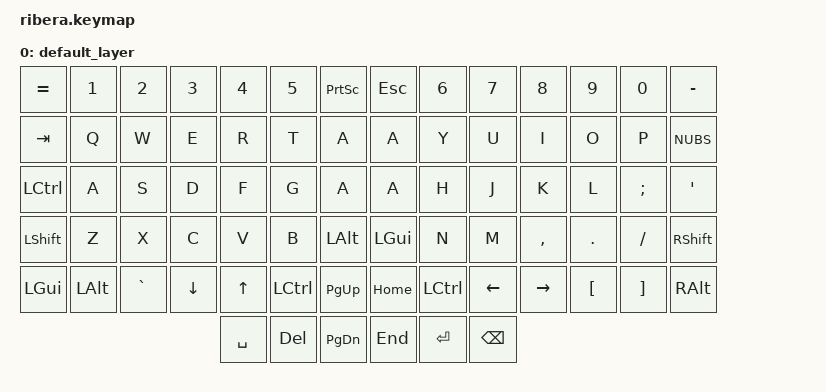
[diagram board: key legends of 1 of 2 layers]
#include <behaviors.dtsi>
#include <dt-bindings/zmk/keys.h>
#include <dt-bindings/zmk/bt.h>

/ {
        keymap {
                compatible = "zmk,keymap";

                default_layer {
// ---------------------------------------------------------------------------------
// |   `  |  1  |  2  |  3  |  4  |  5  |  prt  |       |  6  |  7  |  8  |  9  |  0  | BKSP |
// |  TAB |  Q  |  W  |  E  |  R  |  T  |  Mac  |       |  Y  |  U  |  I  |  O  |  P  |  \   |
// | CAPS |  A  |  S  |  D  |  F  |  G  |  Mac  |       |  H  |  J  |  K  |  L  |  ;  |  ENT |
// | SHFT |  Z  |  X  |  C  |  V  |  B  |               |  N  |  M  |  ,  |  .  |  /  | APOS |
// | CTRL | ALT | GUI | Down | Up | SPC |               | SPC | LOW |LARW |DARW |UARW | RARW |
                        bindings = <
   &kp EQUAL    &kp N1    &kp N2        &kp N3     &kp N4     &kp N5    &kp PSCRN         &kp ESC   &kp N6     &kp N7   &kp N8     &kp N9    &kp N0     &kp MINUS
   &kp TAB      &kp Q     &kp W         &kp E      &kp R      &kp T     &kp A             &kp A     &kp Y      &kp U    &kp I      &kp O     &kp P      &kp NUBS
   &kp LCTRL    &kp A     &kp S         &kp D      &kp F      &kp G     &kp A             &kp A     &kp H      &kp J    &kp K      &kp L     &kp SEMI   &kp APOS
   &kp LSHFT    &kp Z     &kp X         &kp C      &kp V      &kp B     &kp LALT          &kp LGUI  &kp N      &kp M    &kp COMMA   &kp DOT  &kp FSLH   &kp RSHIFT
   &kp LGUI     &kp LALT  &kp GRAVE     &kp DOWN   &kp UP     &kp LCTRL &kp PG_UP         &kp HOME  &kp LCTRL  &kp LEFT &kp RIGHT   &kp LBKT  &kp RBKT  &kp RALT
                                                   &kp SPACE  &kp DEL   &kp PG_DN         &kp END   &kp ENTER  &kp BSPC
                        >;
                };
                lower_layer {
// ------------------------------------------------------------------------------------------------------------
// |       |  BT1  |  BT2  |  BT3  |  BT4  |  BT5  |          |       |       |       |       |       | BTCLR |
// |       |       |       |       |       |       |          |       |       |       |       |       |       |
// |       |       |       | LPAR  | RPAR  |       |          |       | LBKT  | RBKT  |       |       |       |
// |       |       |       |       |       |       |          |       |       |       |       |       |       |
                        bindings = <
   &trans    &bt BT_SEL 0   &bt BT_SEL 1   &bt BT_SEL 2   &bt BT_SEL 3   &bt BT_SEL 4           &trans    &trans    &trans   &trans   &trans  &bt BT_CLR
   &trans    &trans         &trans         &trans         &trans         &trans                 &trans    &trans    &trans   &trans   &trans  &trans
   &trans    &trans         &trans         &kp LPAR       &kp RPAR       &trans                 &trans    &kp LBKT  &kp RBKT &kp MINUS   &kp EQUAL  &trans
   &trans    &trans         &trans         &trans         &trans         &trans                 &trans    &trans    &trans   &trans   &trans  &trans
                        >;
                };
        };
};
